VERSION ""

NS_ :

BS_:

BU_: Computer PDU_HIL VCU_HIL

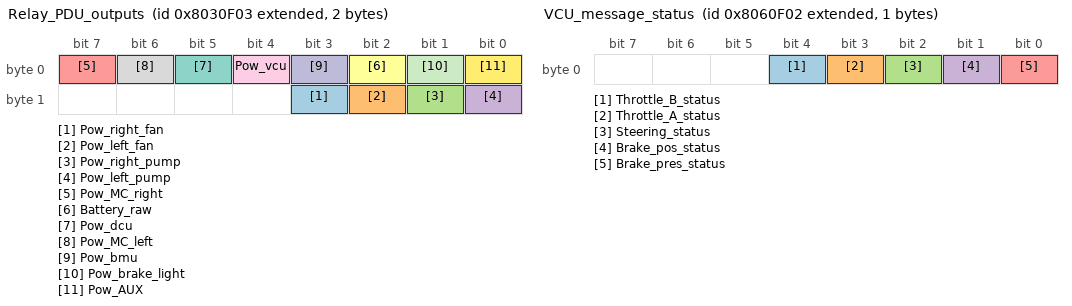
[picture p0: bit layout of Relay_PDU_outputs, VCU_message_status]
BO_ 2281901827 Relay_PDU_outputs: 2 PDU_HIL
 SG_ Pow_right_fan : 11|1@1+ (1,0) [0|1] ""  Computer
 SG_ Pow_left_fan : 10|1@1+ (1,0) [0|1] ""  Computer
 SG_ Pow_right_pump : 9|1@1+ (1,0) [0|1] ""  Computer
 SG_ Pow_left_pump : 8|1@1+ (1,0) [0|1] ""  Computer
 SG_ Pow_MC_right : 7|1@1+ (1,0) [0|1] ""  Computer
 SG_ Battery_raw : 2|1@1+ (1,0) [0|1] ""  Computer
 SG_ Pow_dcu : 5|1@1+ (1,0) [0|1] ""  Computer
 SG_ Pow_MC_left : 6|1@1+ (1,0) [0|1] ""  Computer
 SG_ Pow_vcu : 4|1@1+ (1,0) [0|1] ""  Computer
 SG_ Pow_bmu : 3|1@1+ (1,0) [0|1] ""  Computer
 SG_ Pow_brake_light : 1|1@1+ (1,0) [0|1] ""  Computer
 SG_ Pow_AUX : 0|1@1+ (1,0) [0|1] ""  Computer

BO_ 2281836291 PDU_message_status: 1 PDU_HIL
 SG_ Batt_thermistor_status : 0|1@1+ (1,0) [0|1] ""  Computer

BO_ 2214658831 Batt_thermistor: 3 Computer
 SG_ Batt_thermistor : 0|18@1+ (1,0) [60|200060] "Ohm"  PDU_HIL

BO_ 2282098434 VCU_message_status: 1 VCU_HIL
 SG_ Throttle_B_status : 4|1@1+ (1,0) [0|1] ""  Computer
 SG_ Throttle_A_status : 3|1@1+ (1,0) [0|1] ""  Computer
 SG_ Steering_status : 2|1@1+ (1,0) [0|1] ""  Computer
 SG_ Brake_pos_status : 1|1@1+ (1,0) [0|1] ""  Computer
 SG_ Brake_pres_status : 0|1@1+ (1,0) [0|1] ""  Computer

BO_ 2214920719 Steering_raw: 2 Computer
 SG_ Steering_raw : 0|12@1+ (1,0) [0|3300] "mV"  VCU_HIL

BO_ 2214855183 Brake_position: 2 Computer
 SG_ Brake_position : 0|12@1+ (1,0) [0|3300] "mV"  VCU_HIL

BO_ 2214789647 Brake_pres_raw: 2 Computer
 SG_ Brake_pres_raw : 0|12@1+ (1,0) [0|3300] "mV"  VCU_HIL

BO_ 2214724111 Throttle_position_B: 2 Computer
 SG_ Throttle_position_B : 0|12@1+ (1,0) [0|3300] "mV"  VCU_HIL

BO_ 2214658575 Throttle_position_A: 2 Computer
 SG_ Throttle_position_A : 0|12@1+ (1,0) [0|3300] "mV"  VCU_HIL

CM_ SG_ 2214658575 Throttle_position_A "
";
BA_DEF_  "BusType" STRING ;
BA_DEF_DEF_  "BusType" "CAN";
